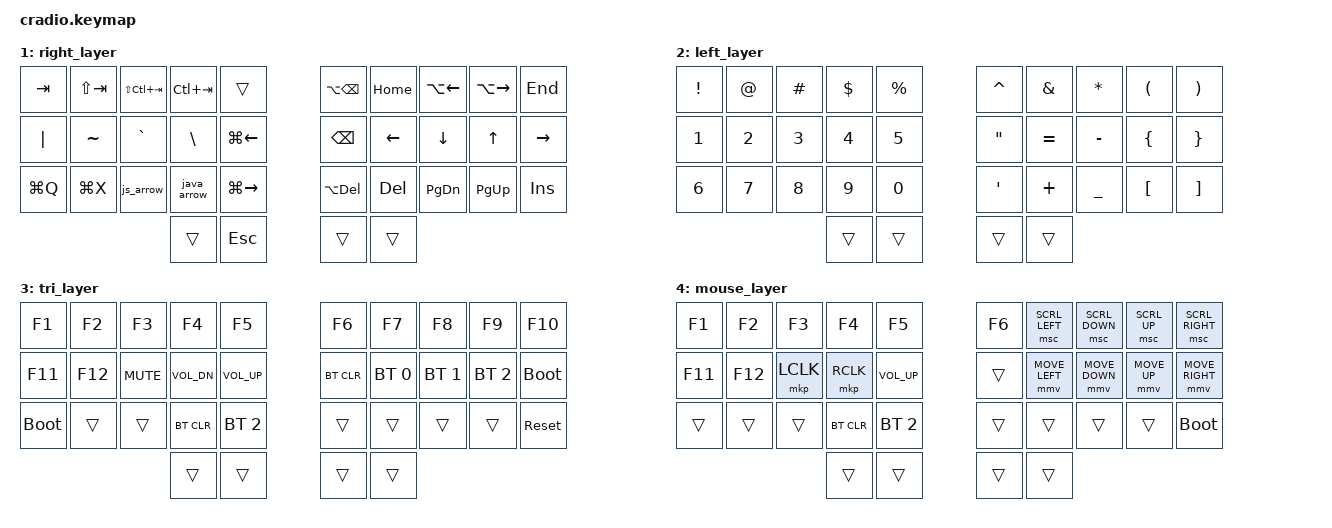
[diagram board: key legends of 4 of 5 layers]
// Copyright (c) 2022 The ZMK Contributors
// SPDX-License-Identifier: MIT

#include <behaviors.dtsi>
#include <dt-bindings/zmk/keys.h>
#include <dt-bindings/zmk/bt.h>
#include <dt-bindings/zmk/pointing.h>
#include <dt-bindings/zmk/mouse.h>

// Mouse velocity 
#define ZMK_POINTING_DEFAULT_MOVE_VAL 1500  // default: 600
#define ZMK_POINTING_DEFAULT_SCRL_VAL 20    // default: 10

// Home row mods macro
#define HRML(k1,k2,k3,k4) &ht LCTRL k1  &ht LALT k2  &ht LGUI k3  &ht LSHFT k4
#define HRMR(k1,k2,k3,k4) &ht RSHFT k1  &ht RGUI k2  &ht RALT k3  &ht RCTRL k4
/ {
    macros {
        js_arrow: javascript_arrow_macro {
            compatible = "zmk,behavior-macro";
            label = "JS_ARROW";
            #binding-cells = <0>;
            bindings = <&kp EQUAL &kp LS(V)>;
        };
        java_arrow: java_arrow_macro {
            compatible = "zmk,behavior-macro";
            label = "JAVA_ARROW";
            #binding-cells = <0>;
            bindings = <&kp MINUS &kp LS(V)>;
        };
    };
    combos {
        compatible = "zmk,combos";
        combo_grave {
            timeout-ms = <50>;
            key-positions = <22 23>;
            bindings = <&kp GRAVE>;
        };
        combo_tidle {
            timeout-ms = <50>;
            key-positions = <20 21>;
            bindings = <&kp TILDE>;
        };
        combo_pipe {
            timeout-ms = <50>;
            key-positions = <8 9>;
            bindings = <&kp PIPE>;
        };
        combo_backslash {
            timeout-ms = <50>;
            key-positions = <28 29>;
            bindings = <&kp BSLH>;
        };
        combo_underscore {
            timeout-ms = <50>;
            key-positions = <32 33>;
            bindings = <&kp UNDER>;
        };
        combo_esc {
            timeout-ms = <50>;
            key-positions = <31 33>;
            bindings = <&kp ESC>;
        };
    };
    behaviors {
        ht: hold_tap {
            compatible = "zmk,behavior-hold-tap";
            #binding-cells = <2>;
            flavor = "tap-preferred";
            tapping-term-ms = <200>;
            quick-tap-ms = <0>;
            bindings = <&kp>, <&kp>;
        };
        sht: short_hold_tap {
            compatible = "zmk,behavior-hold-tap";
            #binding-cells = <2>;
            flavor = "tap-preferred";
            tapping-term-ms = <150>;
            quick-tap-ms = <0>;
            bindings = <&kp>, <&kp>;
        };
        slt: short_layer_tap {
            compatible = "zmk,behavior-hold-tap";
            #binding-cells = <2>;
            flavor = "tap-preferred";
            tapping-term-ms = <150>;
            quick-tap-ms = <0>;
            bindings = <&mo>, <&kp>;
        };
    };

    conditional_layers {
        compatible = "zmk,conditional-layers";
        tri_layer {
            if-layers = <1 2>;
            then-layer = <3>;
        };
    };

    keymap {
        compatible = "zmk,keymap";
        default_layer {
            bindings = <
        //╭──────────┬──────────┬──────────┬──────────┬──────────╮   ╭──────────┬──────────┬──────────┬──────────┬──────────╮
        //│  Q       │  W       │  E       │  R       │  T       │   │  Y       │  U       │  I       │  O       │  P       │
            &lt 4 Q      &kp W      &kp E      &kp R      &kp T          &kp Y      &kp U      &kp I      &kp O      &kp P
        //├──────────┼──────────┼──────────┼──────────┼──────────┤   ├──────────┼──────────┼──────────┼──────────┼──────────┤
        //│  A       │  S       │  D       │  F       │  G       │   │  H       │  J       │  K       │  L       │ ;        │
            HRML(A,        S,         D,         F)     &kp G          &kp H      HRMR(J,        K,         L,        SEMI)
        //├──────────┼──────────┼──────────┼──────────┼──────────┤   ├──────────┼──────────┼──────────┼──────────┼──────────┤
        //│  Z       │  X       │  C       │  V       │  B       │   │  N       │  M       │ , <      │ . >      │ / ?      │
            &kp Z      &kp X      &kp C      &kp V      &kp B          &kp N      &kp M      &kp COMMA  &kp DOT    &kp FSLH
        //╰──────────┴──────────┴──────────┼──────────┼──────────┤   ├──────────┼──────────┼──────────┴──────────┴──────────╯
                                        &mo 2  &sht RSHFT ENTER &sht LS(LC(LA(LGUI)))SPACE &slt 1 BSPC
        //                                 ╰──────────┴──────────╯   ╰──────────┴──────────╯
            >;
        };
    
    
        right_layer {
            bindings = <
        //╭──────────┬──────────┬──────────┬──────────┬──────────╮   ╭──────────┬──────────┬──────────┬──────────┬──────────╮
        //│ TAB      │SHIFT(TAB)│S(C(TAB)) │ CTRL(TAB)│          │   │ OPT(BSPC)│  HOME    │ LA(LEFT) │ LA(RIGHT)│ END      │
            &kp TAB &kp LS(TAB) &kp LS(LC(TAB)) &kp LC(TAB) &trans   &kp LA(BSPC) &kp HOME  &kp LA(LEFT) &kp LA(RIGHT) &kp END
        //├──────────┼──────────┼──────────┼──────────┼──────────┤   ├──────────┼──────────┼──────────┼──────────┼──────────┤
        //│  |       │  _       │  `       │  \       │CMD(LEFT) │   │  BSPC    │ LEFT     │ DOWN     │ UP       │  RIGHT   │
            &kp PIPE  &kp TILDE  &kp GRAVE  &kp BSLH   &kp LG(LEFT)    &kp BSPC &kp LEFT   &kp DOWN   &kp UP   &kp RIGHT
        //├──────────┼──────────┼──────────┼──────────┼──────────┤   ├──────────┼──────────┼──────────┼──────────┼──────────┤
        //│ CMD(Q)   │  CUT     │  COPY    │  PASTE   │CMD(RIGHT)│   │ OPT(DEL) │ DELETE   │  PAGE DN │  PAGE UP │  INSERT  │
            &kp LG(Q)  &kp LG(X) &js_arrow  &java_arrow &kp LG(RIGHT)    &kp LA(DEL) &kp DEL   &kp PG_DN   &kp PG_UP &kp INS 
        //╰──────────┴──────────┴──────────┼──────────┼──────────┤   ├──────────┼──────────┼──────────┴──────────┴──────────╯
                                             &trans     &kp ESC        &trans     &trans
        //                                 ╰──────────┴──────────╯   ╰──────────┴──────────╯
            >;
        };

        left_layer {
            bindings = <
        //╭──────────┬──────────┬──────────┬──────────┬──────────╮   ╭──────────┬──────────┬──────────┬──────────┬──────────╮
        //│  !       │  @       │  #       │  $       │  %       │   │  ^       │  &       │  *       │  (       │  )       │
            &kp EXCL   &kp AT     &kp HASH   &kp DLLR   &kp PRCNT      &kp CARET &kp AMPS   &kp ASTRK   &kp LPAR   &kp RPAR
        //├──────────┼──────────┼──────────┼──────────┼──────────┤   ├──────────┼──────────┼──────────┼──────────┼──────────┤
        //│  1       │  2       │  3       │  4       │  5       │   │  "       │  =       │  -       │  {       │  }       │
            &kp N1    &kp N2     &kp N3     &kp N4     &kp N5           &kp DQT   &kp EQUAL   &kp MINUS  &kp LBRC  &kp RBRC
        //├──────────┼──────────┼──────────┼──────────┼──────────┤   ├──────────┼──────────┼──────────┼──────────┼──────────┤
        //│  6       │          │          │  _       │          │   │  /       │  +       │  "       │  [       │  ]       │
            &kp N6    &kp N7     &kp N8     &kp N9     &kp N0          &kp SQT  &kp PLUS  &kp UNDER   &kp LBKT   &kp RBKT
        //╰──────────┴──────────┴──────────┼──────────┼──────────┤   ├──────────┼──────────┼──────────┴──────────┴──────────╯
                                             &trans     &trans         &trans &trans
        //                                 ╰──────────┴──────────╯   ╰──────────┴──────────╯
            >;
        };

        tri_layer {
            bindings = <
        //╭──────────┬──────────┬──────────┬──────────┬──────────╮   ╭──────────┬──────────┬──────────┬──────────┬──────────╮
        //│ F1       │ F2       │ F3       │ F4       │PROFILE 0 │   │          │          │          │          │          │
           &kp F1      &kp F2     &kp F3     &kp F4     &kp F5          &kp F6     &kp F7     &kp F8     &kp F9     &kp F10
        //├──────────┼──────────┼──────────┼──────────┼──────────┤   ├──────────┼──────────┼──────────┼──────────┼──────────┤
        //│ F11      │ F12      │ MUTE     │VOLUME_DN │ VOLUME_UP│   │          │          │          │          │BOOTLOADER│
           &kp F11    &kp F12   &kp K_MUTE &kp K_VOL_DN &kp K_VOL_UP  &bt BT_CLR &bt BT_SEL 0 &bt BT_SEL 1 &bt BT_SEL 2 &bootloader
        //├──────────┼──────────┼──────────┼──────────┼──────────┤   ├──────────┼──────────┼──────────┼──────────┼──────────┤
        //│BOOTLOADER│          │          │ CLEAR BT │PROFILE 2 │   │          │          │          │          │  RESET   │
           &bootloader &trans     &trans    &bt BT_CLR &bt BT_SEL 2    &trans     &trans     &trans     &trans    &sys_reset
        //╰──────────┴──────────┴──────────┼──────────┼──────────┤   ├──────────┼──────────┼──────────┴──────────┴──────────╯
                                             &trans     &trans         &trans     &trans
        //                                 ╰──────────┴──────────╯   ╰──────────┴──────────╯
            >;
        };
        
        mouse_layer {
            bindings = <
        //╭──────────┬──────────┬──────────┬──────────┬──────────╮   ╭──────────┬──────────┬──────────┬──────────┬──────────╮
        //│ F1       │ F2       │ F3       │ F4       │PROFILE 0 │   │          │          │          │          │          │
           &kp F1      &kp F2     &kp F3     &kp F4     &kp F5      &kp F6 &msc SCRL_LEFT &msc SCRL_DOWN &msc SCRL_UP &msc SCRL_RIGHT
        //├──────────┼──────────┼──────────┼──────────┼──────────┤   ├──────────┼──────────┼──────────┼──────────┼──────────┤
        //│ F11      │ F12      │ L_CLICK  │  R_CLICK │ VOLUME_UP│   │          │          │          │          │BOOTLOADER│
           &kp F11    &kp F12   &mkp LCLK  &mkp RCLK &kp K_VOL_UP  &trans &mmv MOVE_LEFT &mmv MOVE_DOWN &mmv MOVE_UP &mmv MOVE_RIGHT
        //├──────────┼──────────┼──────────┼──────────┼──────────┤   ├──────────┼──────────┼──────────┼──────────┼──────────┤
        //│          │          │ CLEAR BT │PROFILE 2 │   │          │          │          │          │  RESET   │
           &trans      &trans    &trans    &bt BT_CLR &bt BT_SEL 2    &trans     &trans     &trans     &trans    &bootloader
        //╰──────────┴──────────┴──────────┼──────────┼──────────┤   ├──────────┼──────────┼──────────┴──────────┴──────────╯
                                             &trans     &trans         &trans     &trans
        //                                 ╰──────────┴──────────╯   ╰──────────┴──────────╯
            >;
        };

    };
};
